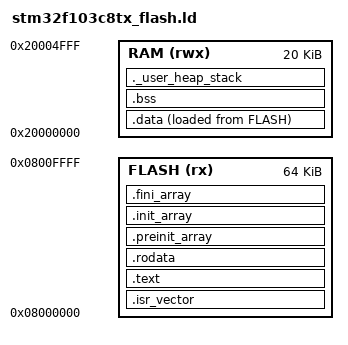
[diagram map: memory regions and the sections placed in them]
/*
 * =============================================================================
 * Linker Script for STM32F103C8T6 (64 KB Flash, 20 KB RAM)
 * Assessment Fixture for Part A Linker Reasoning
 * =============================================================================
 */

ENTRY(Reset_Handler)

MEMORY
{
    FLASH (rx)  : ORIGIN = 0x08000000, LENGTH = 64K
    RAM   (rwx) : ORIGIN = 0x20000000, LENGTH = 20K
}

_estack = ORIGIN(RAM) + LENGTH(RAM);
_min_stack_size = 0x400;

SECTIONS
{
    .isr_vector :
    {
        . = ALIGN(4);
        KEEP(*(.isr_vector))
        . = ALIGN(4);
    } > FLASH

    .text :
    {
        . = ALIGN(4);
        *(.text)
        *(.text*)
        *(.glue_7)
        *(.glue_7t)
        *(.eh_frame)
        KEEP (*(.init))
        KEEP (*(.fini))
        . = ALIGN(4);
        _etext = .;
    } > FLASH

    .rodata :
    {
        . = ALIGN(4);
        *(.rodata)
        *(.rodata*)
        . = ALIGN(4);
    } > FLASH

    .preinit_array :
    {
        . = ALIGN(4);
        PROVIDE_HIDDEN (__preinit_array_start = .);
        KEEP (*(.preinit_array*))
        PROVIDE_HIDDEN (__preinit_array_end = .);
        . = ALIGN(4);
    } > FLASH

    .init_array :
    {
        . = ALIGN(4);
        PROVIDE_HIDDEN (__init_array_start = .);
        KEEP (*(SORT(.init_array.*)))
        KEEP (*(.init_array*))
        PROVIDE_HIDDEN (__init_array_end = .);
        . = ALIGN(4);
    } > FLASH

    .fini_array :
    {
        . = ALIGN(4);
        PROVIDE_HIDDEN (__fini_array_start = .);
        *(SORT(.fini_array.*))
        *(.fini_array*)
        PROVIDE_HIDDEN (__fini_array_end = .);
        . = ALIGN(4);
    } > FLASH

    /*
     * Linker configuration for initialized data relocation.
     * Note: Section load and virtual memory addresses must align with C runtime startup copy loop.
     */
    _sidata = _etext;

    .data :
    {
        . = ALIGN(4);
        _sdata = .;
        *(.data)
        *(.data*)
        . = ALIGN(4);
        _edata = .;
    } > RAM AT > FLASH

    .bss :
    {
        . = ALIGN(4);
        _sbss = .;
        *(.bss)
        *(.bss*)
        *(COMMON)
        . = ALIGN(4);
        _ebss = .;
    } > RAM

    ._user_heap_stack :
    {
        . = ALIGN(8);
        PROVIDE ( end = . );
        PROVIDE ( _end = . );
        . = . + _min_stack_size;
        . = ALIGN(8);
    } > RAM

    /DISCARD/ :
    {
        libc.a ( * )
        libm.a ( * )
        libgcc.a ( * )
    }

    .ARM.attributes 0 : { *(.ARM.attributes) }
}
